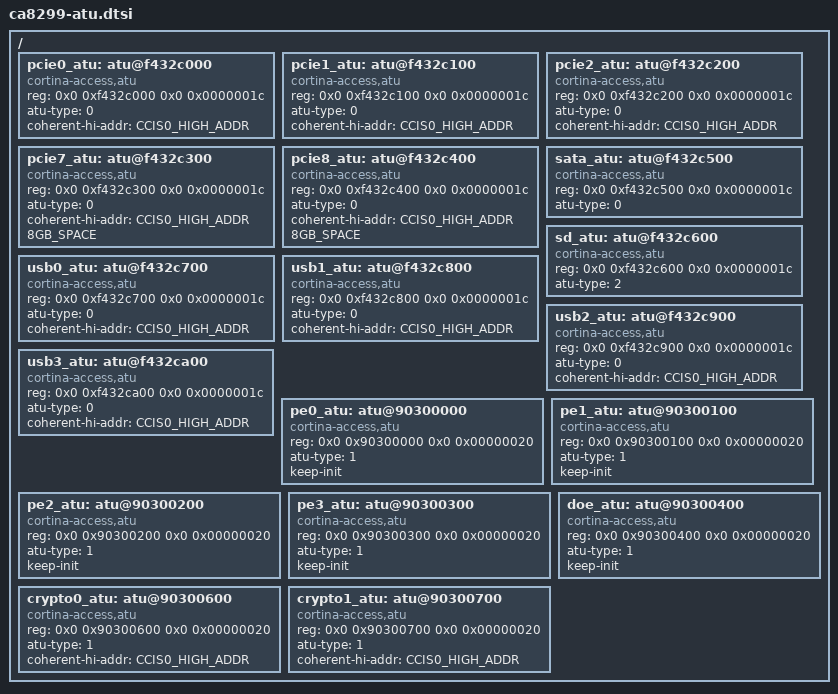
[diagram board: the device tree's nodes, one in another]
// SPDX-License-Identifier: GPL-2.0

#define CCIS0_HIGH_ADDR 0x4

/ {
	pcie0_atu: atu@f432c000 {
		compatible = "cortina-access,atu";
		reg = <0x0 0xf432c000 0x0 0x0000001c>;
		reg-names = "pcie0_atu";
		atu-type = <0>;
		coherent-hi-addr = <CCIS0_HIGH_ADDR>;
		#iommu-cells = <0>;
	};
	pcie1_atu: atu@f432c100 {
		compatible = "cortina-access,atu";
		reg = <0x0 0xf432c100 0x0 0x0000001c>;
		reg-names = "pcie1_atu";
		atu-type = <0>;
		coherent-hi-addr = <CCIS0_HIGH_ADDR>;
		#iommu-cells = <0>;
	};
	pcie2_atu: atu@f432c200 {
		compatible = "cortina-access,atu";
		reg = <0x0 0xf432c200 0x0 0x0000001c>;
		reg-names = "pcie2_atu";
		atu-type = <0>;
		coherent-hi-addr = <CCIS0_HIGH_ADDR>;
		#iommu-cells = <0>;
	};
	pcie7_atu: atu@f432c300 {
		compatible = "cortina-access,atu";
		reg = <0x0 0xf432c300 0x0 0x0000001c>;
		reg-names = "pcie7_atu";
		atu-type = <0>;
		coherent-hi-addr = <CCIS0_HIGH_ADDR>;
		#iommu-cells = <0>;
		8GB_SPACE;
	};
	pcie8_atu: atu@f432c400 {
		compatible = "cortina-access,atu";
		reg = <0x0 0xf432c400 0x0 0x0000001c>;
		reg-names = "pcie8_atu";
		atu-type = <0>;
		coherent-hi-addr = <CCIS0_HIGH_ADDR>;
		#iommu-cells = <0>;
		8GB_SPACE;
	};
	sata_atu: atu@f432c500 {
		compatible = "cortina-access,atu";
		reg = <0x0 0xf432c500 0x0 0x0000001c>;
		reg-names = "sata_atu";
		atu-type = <0>;
		#iommu-cells = <0>;
	};
	sd_atu: atu@f432c600 {
		compatible = "cortina-access,atu";
		reg = <0x0 0xf432c600 0x0 0x0000001c>;
		reg-names = "sd_atu";
		atu-type = <2>;
		#iommu-cells = <0>;
	};
	usb0_atu: atu@f432c700 {
		compatible = "cortina-access,atu";
		reg = <0x0 0xf432c700 0x0 0x0000001c>;
		reg-names = "usb0_atu";
		atu-type = <0>;
		coherent-hi-addr = <CCIS0_HIGH_ADDR>;
		#iommu-cells = <0>;
	};
	usb1_atu: atu@f432c800 {
		compatible = "cortina-access,atu";
		reg = <0x0 0xf432c800 0x0 0x0000001c>;
		reg-names = "usb1_atu";
		atu-type = <0>;
		coherent-hi-addr = <CCIS0_HIGH_ADDR>;
		#iommu-cells = <0>;
	};
	usb2_atu: atu@f432c900 {
		compatible = "cortina-access,atu";
		reg = <0x0 0xf432c900 0x0 0x0000001c>;
		reg-names = "usb2_atu";
		atu-type = <0>;
		coherent-hi-addr = <CCIS0_HIGH_ADDR>;
		#iommu-cells = <0>;
	};
	usb3_atu: atu@f432ca00 {
		compatible = "cortina-access,atu";
		reg = <0x0 0xf432ca00 0x0 0x0000001c>;
		reg-names = "usb3_atu";
		atu-type = <0>;
		coherent-hi-addr = <CCIS0_HIGH_ADDR>;
		#iommu-cells = <0>;
	};
	pe0_atu: atu@90300000 {
		compatible = "cortina-access,atu";
		reg = <0x0 0x90300000 0x0 0x00000020>;
		reg-names = "pe0_atu";
		atu-type = <1>;
		#iommu-cells = <0>;
		keep-init;
	};
	pe1_atu: atu@90300100 {
		compatible = "cortina-access,atu";
		reg = <0x0 0x90300100 0x0 0x00000020>;
		reg-names = "pe1_atu";
		atu-type = <1>;
		#iommu-cells = <0>;
		keep-init;
	};
	pe2_atu: atu@90300200 {
		compatible = "cortina-access,atu";
		reg = <0x0 0x90300200 0x0 0x00000020>;
		reg-names = "pe2_atu";
		atu-type = <1>;
		#iommu-cells = <0>;
		keep-init;
	};
	pe3_atu: atu@90300300 {
		compatible = "cortina-access,atu";
		reg = <0x0 0x90300300 0x0 0x00000020>;
		reg-names = "pe3_atu";
		atu-type = <1>;
		#iommu-cells = <0>;
		keep-init;
	};
	doe_atu: atu@90300400 {
		compatible = "cortina-access,atu";
		reg = <0x0 0x90300400 0x0 0x00000020>;
		reg-names = "doe_atu";
		atu-type = <1>;
		#iommu-cells = <0>;
		keep-init;
	};
	crypto0_atu: atu@90300600 {
		compatible = "cortina-access,atu";
		reg = <0x0 0x90300600 0x0 0x00000020>;
		reg-names = "crypto0_atu";
		atu-type = <1>;
		coherent-hi-addr = <CCIS0_HIGH_ADDR>;
		#iommu-cells = <0>;
	};
	crypto1_atu: atu@90300700 {
		compatible = "cortina-access,atu";
		reg = <0x0 0x90300700 0x0 0x00000020>;
		reg-names = "crypto1_atu";
		atu-type = <1>;
		coherent-hi-addr = <CCIS0_HIGH_ADDR>;
		#iommu-cells = <0>;
	};
};
